# rtc_reva_me55 register map
Registers are access not given, no defined reset value unless marked. A register's access mark holds for its fields unless they carry their own. Offsets are from the block's base; lines under a group give offsets from that group; [hi:lo] are bit positions; {n}, {i} and the like mark numbered series; 'fields as' and 'values as' point back to an identical list; <NAME> marks a mode.

## Memory map
0x40006000 RTC size 0x400 — Real Time Clock and Alarm.

## Interrupts
3 RTC — RTC interrupt.

## RTC — Real Time Clock and Alarm.
Base 0x40006000
0x00 SEC — RTC Second Counter. This register contains the 32-bit second counter.
  [31:0] SEC — Seconds Counter.
0x04 SSEC — RTC Sub-second Counter. This counter increments at 256Hz. RTC_SEC is incremented when this register rolls over from 0xFF to 0x00.
  [11:0] SSEC — Sub-Seconds Counter (12-bit).
0x08 TODA — Time-of-day Alarm.
  [19:0] TOD_ALARM
0x0C SSECA — RTC sub-second alarm. This register contains the reload value for the sub-second alarm.
  [31:0] SSEC_ALARM — This register contains the reload value for the sub-second alarm.
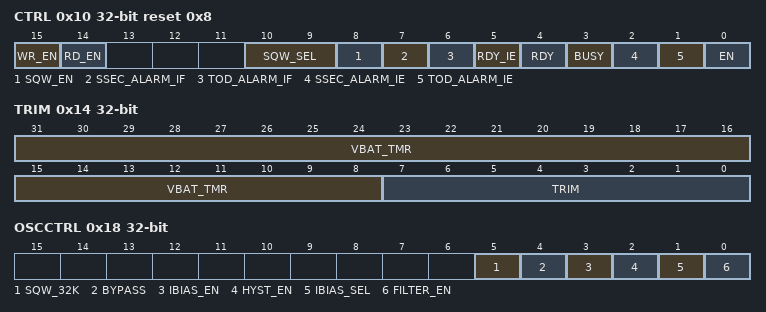
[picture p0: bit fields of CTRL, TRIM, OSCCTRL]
0x10 CTRL reset 0x8 — RTC Control Register.
  [15] WR_EN — Write Enable. This register bit serves as a protection mechanism against unintentional writes to critical RTC bits.
    0=Ignored; 1=Allowed
  [14] RD_EN — Asynchronous Counter Read Enable.
    0=Synchronous; 1=Asynchronous
  [10:9] SQW_SEL — Frequency Output Selection. When SQE=1, these bits specify the output frequency on the SQW pin.
    0=freq1Hz (1 Hz (Compensated).); 1=freq512Hz (512 Hz (Compensated).); 2=freq4KHz (4 KHz.); 3=clkDiv8 (RTC Input Clock / 8.)
  [8] SQW_EN — Square Wave Output Enable.
    0=dis (Disable.); 1=en (Enable.)
  [7] SSEC_ALARM_IF ro — Sub-second Alarm Interrupt Flag. This alarm is qualified as wake-up source to the processor.
    0=inactive (Not active.); 1=pending (Active.)
  [6] TOD_ALARM_IF ro — Time-of-Day Alarm Interrupt Flag. This alarm is qualified as wake-up source to the processor.
    0=inactive (Not active.); 1=pending (Active.)
  [5] RDY_IE — RTC Ready Interrupt Enable.
    0=dis (Disable.); 1=en (Enable.)
  [4] RDY — RTC Ready. This bit is set to 1 by hardware when the RTC count registers update. It can be cleared to 0 by software at any time. It will also be cleared to 0 by hardware just prior to an update of the RTC count register.
    0=busy (Register has not updated.); 1=ready
  [3] BUSY ro — RTC Busy. This bit is set to 1 by hardware when changes to RTC registers required a synchronized version of the register to be in place. This bit is automatically cleared by hardware.
    0=idle; 1=busy
  [2] SSEC_ALARM_IE — Alarm Sub-second Interrupt Enable. Change to this bit is effective only after BUSY is cleared from 1 to 0.
    0=dis (Disable.); 1=en (Enable.)
  [1] TOD_ALARM_IE — Alarm Time-of-Day Interrupt Enable. Change to this bit is effective only after BUSY is cleared from 1 to 0.
    0=dis (Disable.); 1=en (Enable.)
  [0] EN — Real Time Clock Enable. This bit enables the Real Time Clock. This bit can only be written when WE=1 and BUSY =0. Change to this bit is effective only after BUSY is cleared from 1 to 0.
    0=dis (Disable.); 1=en (Enable.)
0x14 TRIM — RTC Trim Register.
  [31:8] VBAT_TMR — VBAT Timer Value. When RTC is running off of VBAT, this field is incremented every 32 seconds.
  [7:0] TRIM — RTC Trim. This register contains the 2's complement value that specifies the trim resolution. Each increment or decrement of the bit adds or subtracts 1ppm at each 4KHz clock value, with a maximum correction of +/- 127ppm.
0x18 OSCCTRL — RTC Oscillator Control Register.
  [5] SQW_32K — RTC 32kHz Square Wave Output
    0=dis (Disable.); 1=en (Enable.)
  [4] BYPASS — RTC Crystal Bypass
    0=dis (Disable.); 1=en (Enable.)
  [3] IBIAS_EN — RTC IBIAS Enable.
  [2] HYST_EN — RTC Hysteresis Enable.
  [1] IBIAS_SEL — IBIAS Select.
    0=2x; 1=4x
  [0] FILTER_EN — Enable Filter.
